AUTOSAR XML (schema 4.0)
package /CommandParserComponent
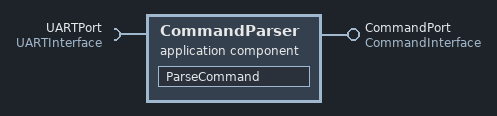
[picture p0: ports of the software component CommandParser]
  application software component type CommandParser
    require port UARTPort: provided-interface=UARTInterface
    provide port CommandPort: required-interface=CommandInterface
    internal behavior CommandParserBehavior
      runnable ParseCommand
